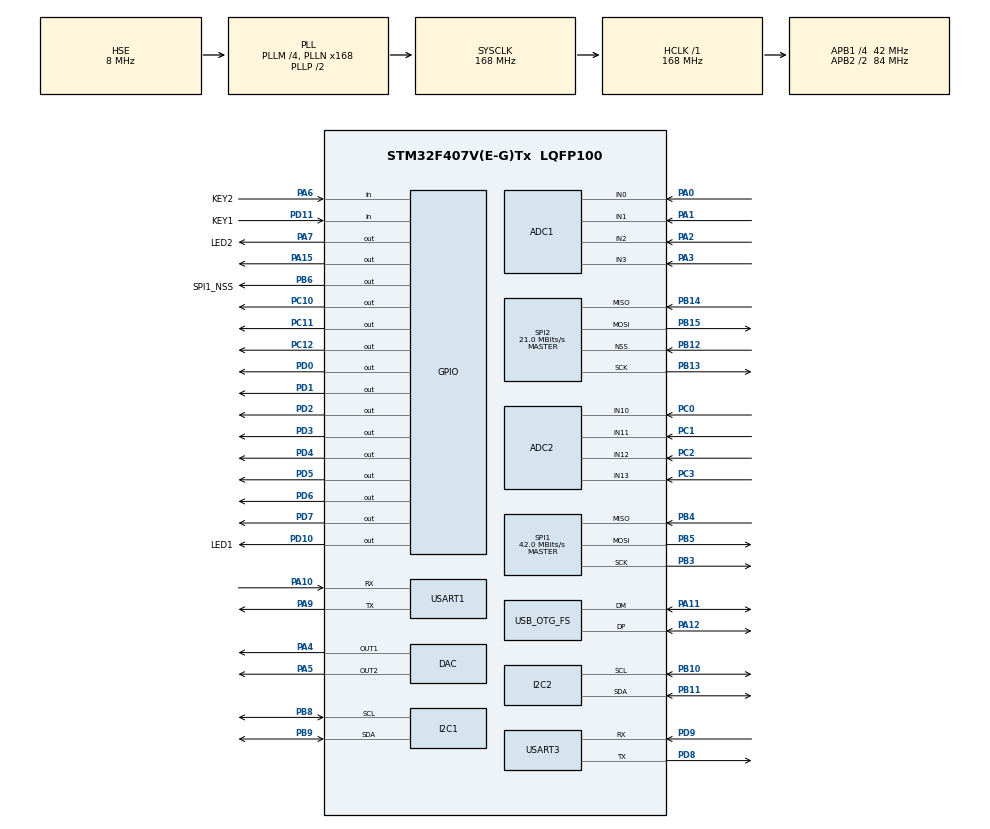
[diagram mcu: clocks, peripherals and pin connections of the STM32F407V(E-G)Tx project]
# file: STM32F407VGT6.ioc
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ADC1.Channel-66\#ChannelRegularConversion=ADC_CHANNEL_0
ADC1.ClockPrescaler=ADC_CLOCK_SYNC_PCLK_DIV4
ADC1.NbrOfConversionFlag=1
ADC1.Rank-66\#ChannelRegularConversion=1
ADC1.SamplingTime-66\#ChannelRegularConversion=ADC_SAMPLETIME_3CYCLES
ADC1.master=1
ADC2.Channel-42\#ChannelRegularConversion=ADC_CHANNEL_10
ADC2.ClockPrescaler=ADC_CLOCK_SYNC_PCLK_DIV4
ADC2.NbrOfConversionFlag=1
ADC2.Rank-42\#ChannelRegularConversion=1
ADC2.SamplingTime-42\#ChannelRegularConversion=ADC_SAMPLETIME_3CYCLES
Mcu.Family=STM32F4
Mcu.Name=STM32F407V(E-G)Tx
Mcu.Package=LQFP100
NVIC.PriorityGroup=NVIC_PRIORITYGROUP_4
PA0-WKUP.Signal=ADCx_IN0
PA1.Signal=ADCx_IN1
PA10.Mode=Asynchronous
PA10.Signal=USART1_RX
PA11.Mode=Device_Only
PA11.Signal=USB_OTG_FS_DM
PA12.Mode=Device_Only
PA12.Signal=USB_OTG_FS_DP
PA13.Mode=Serial_Wire
PA13.Signal=SYS_JTMS-SWDIO
PA14.Mode=Serial_Wire
PA14.Signal=SYS_JTCK-SWCLK
PA15.Signal=GPIO_Output
PA2.Signal=ADCx_IN2
PA3.Signal=ADCx_IN3
PA4.Signal=COMP_DAC1_group
PA5.Signal=COMP_DAC2_group
PA6.GPIO_Label=KEY2
PA6.Signal=GPIO_Input
PA7.GPIO_Label=LED2
PA7.Signal=GPIO_Output
PA9.Mode=Asynchronous
PA9.Signal=USART1_TX
PB10.Mode=I2C
PB10.Signal=I2C2_SCL
PB11.Mode=I2C
PB11.Signal=I2C2_SDA
PB12.Mode=NSS_Signal_Hard_Input
PB12.Signal=SPI2_NSS
PB13.Mode=Full_Duplex_Master
PB13.Signal=SPI2_SCK
PB14.Mode=Full_Duplex_Master
PB14.Signal=SPI2_MISO
PB15.Mode=Full_Duplex_Master
PB15.Signal=SPI2_MOSI
PB3.Mode=Full_Duplex_Master
PB3.Signal=SPI1_SCK
PB4.Mode=Full_Duplex_Master
PB4.Signal=SPI1_MISO
PB5.Mode=Full_Duplex_Master
PB5.Signal=SPI1_MOSI
PB6.GPIO_Label=SPI1_NSS
PB6.Signal=GPIO_Output
PB8.Mode=I2C
PB8.Signal=I2C1_SCL
PB9.Mode=I2C
PB9.Signal=I2C1_SDA
PC0.Signal=ADCx_IN10
PC1.Signal=ADCx_IN11
PC10.Signal=GPIO_Output
PC11.Signal=GPIO_Output
PC12.Signal=GPIO_Output
PC14-OSC32_IN.Mode=LSE-External-Oscillator
PC14-OSC32_IN.Signal=RCC_OSC32_IN
PC15-OSC32_OUT.Mode=LSE-External-Oscillator
PC15-OSC32_OUT.Signal=RCC_OSC32_OUT
PC2.Signal=ADCx_IN12
PC3.Signal=ADCx_IN13
PD0.Signal=GPIO_Output
PD1.Signal=GPIO_Output
PD10.GPIO_Label=LED1
PD10.Signal=GPIO_Output
PD11.GPIO_Label=KEY1
PD11.Signal=GPIO_Input
PD2.Signal=GPIO_Output
PD3.Signal=GPIO_Output
PD4.Signal=GPIO_Output
PD5.Signal=GPIO_Output
PD6.Signal=GPIO_Output
PD7.Signal=GPIO_Output
PD8.Mode=Asynchronous
PD8.Signal=USART3_TX
PD9.Mode=Asynchronous
PD9.Signal=USART3_RX
PH0-OSC_IN.Mode=HSE-External-Oscillator
PH0-OSC_IN.Signal=RCC_OSC_IN
PH1-OSC_OUT.Mode=HSE-External-Oscillator
PH1-OSC_OUT.Signal=RCC_OSC_OUT
ProjectManager.HeapSize=0x200
ProjectManager.StackSize=0x400
ProjectManager.TargetToolchain=MDK-ARM V5
RCC.48MHZClocksFreq_Value=48000000
RCC.AHBFreq_Value=168000000
RCC.APB1CLKDivider=RCC_HCLK_DIV4
RCC.APB1Freq_Value=42000000
RCC.APB1TimFreq_Value=84000000
RCC.APB2CLKDivider=RCC_HCLK_DIV2
RCC.APB2Freq_Value=84000000
RCC.APB2TimFreq_Value=168000000
RCC.CortexFreq_Value=168000000
RCC.HCLKFreq_Value=168000000
RCC.HSE_VALUE=8000000
RCC.HSI_VALUE=16000000
RCC.PLLM=4
RCC.PLLN=168
RCC.PLLQ=7
RCC.SYSCLKFreq_VALUE=168000000
RCC.SYSCLKSource=RCC_SYSCLKSOURCE_PLLCLK
RCC.VCOOutputFreq_Value=336000000
SH.ADCx_IN0.0=ADC1_IN0,IN0
SH.ADCx_IN1.0=ADC1_IN1,IN1
SH.ADCx_IN10.0=ADC2_IN10,IN10
SH.ADCx_IN11.0=ADC2_IN11,IN11
SH.ADCx_IN12.0=ADC2_IN12,IN12
SH.ADCx_IN13.0=ADC2_IN13,IN13
SH.ADCx_IN2.0=ADC1_IN2,IN2
SH.ADCx_IN3.0=ADC1_IN3,IN3
SH.COMP_DAC1_group.0=DAC_OUT1,DAC_OUT1
SH.COMP_DAC2_group.0=DAC_OUT2,DAC_OUT2
SPI1.CalculateBaudRate=42.0 MBits/s
SPI1.Direction=SPI_DIRECTION_2LINES
SPI1.Mode=SPI_MODE_MASTER
SPI1.VirtualType=VM_MASTER
SPI2.CalculateBaudRate=21.0 MBits/s
SPI2.Direction=SPI_DIRECTION_2LINES
SPI2.Mode=SPI_MODE_MASTER
SPI2.VirtualNSS=VM_NSSHARD
SPI2.VirtualType=VM_MASTER
USART1.VirtualMode=VM_ASYNC
USART3.VirtualMode=VM_ASYNC
USB_OTG_FS.VirtualMode=Device_Only
board=custom

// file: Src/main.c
/**
  ******************************************************************************
  * @file           : main.c
  * @brief          : Main program body
  ******************************************************************************
  ** This notice applies to any and all portions of this file
  * that are not between comment pairs USER CODE BEGIN and
  * USER CODE END. Other portions of this file, whether
  * inserted by the user or by software development tools
  * are owned by their respective copyright owners.
  *
  * COPYRIGHT(c) 2019 STMicroelectronics
  *
  * Redistribution and use in source and binary forms, with or without modification,
  * are permitted provided that the following conditions are met:
  *   1. Redistributions of source code must retain the above copyright notice,
  *      this list of conditions and the following disclaimer.
  *   2. Redistributions in binary form must reproduce the above copyright notice,
  *      this list of conditions and the following disclaimer in the documentation
  *      and/or other materials provided with the distribution.
  *   3. Neither the name of STMicroelectronics nor the names of its contributors
  *      may be used to endorse or promote products derived from this software
  *      without specific prior written permission.
  *
  * THIS SOFTWARE IS PROVIDED BY THE COPYRIGHT HOLDERS AND CONTRIBUTORS "AS IS"
  * AND ANY EXPRESS OR IMPLIED WARRANTIES, INCLUDING, BUT NOT LIMITED TO, THE
  * IMPLIED WARRANTIES OF MERCHANTABILITY AND FITNESS FOR A PARTICULAR PURPOSE ARE
  * DISCLAIMED. IN NO EVENT SHALL THE COPYRIGHT HOLDER OR CONTRIBUTORS BE LIABLE
  * FOR ANY DIRECT, INDIRECT, INCIDENTAL, SPECIAL, EXEMPLARY, OR CONSEQUENTIAL
  * DAMAGES (INCLUDING, BUT NOT LIMITED TO, PROCUREMENT OF SUBSTITUTE GOODS OR
  * SERVICES; LOSS OF USE, DATA, OR PROFITS; OR BUSINESS INTERRUPTION) HOWEVER
  * CAUSED AND ON ANY THEORY OF LIABILITY, WHETHER IN CONTRACT, STRICT LIABILITY,
  * OR TORT (INCLUDING NEGLIGENCE OR OTHERWISE) ARISING IN ANY WAY OUT OF THE USE
  * OF THIS SOFTWARE, EVEN IF ADVISED OF THE POSSIBILITY OF SUCH DAMAGE.
  *
  ******************************************************************************
  */
#include "main.h"
#include "stm32f4xx_hal.h"
#include "adc.h"
#include "dac.h"
#include "i2c.h"
#include "spi.h"
#include "usart.h"
#include "usb_otg.h"
#include "gpio.h"

/* USER CODE BEGIN Includes */
#include "stdio.h"
/* USER CODE END Includes */

/* USER CODE BEGIN PV */
/* Private variables ---------------------------------------------------------*/

/* USER CODE END PV */

void SystemClock_Config(void);

/* USER CODE BEGIN PFP */
/* Private function prototypes -----------------------------------------------*/

/* USER CODE END PFP */

int main(void)
{

  /* MCU Configuration----------------------------------------------------------*/

  /* Reset of all peripherals, Initializes the Flash interface and the Systick. */
  HAL_Init();

  /* Configure the system clock */
  SystemClock_Config();

  /* Initialize all configured peripherals */
  MX_GPIO_Init();
  MX_ADC1_Init();
  MX_ADC2_Init();
  MX_DAC_Init();
  MX_I2C1_Init();
  MX_I2C2_Init();
  MX_SPI1_Init();
  MX_SPI2_Init();
  MX_USART1_UART_Init();
  MX_USART3_UART_Init();
  MX_USB_OTG_FS_PCD_Init();
  /* USER CODE BEGIN 2 */
  printf("init ok!\n");

  /* USER CODE END 2 */

  /* Infinite loop */
  /* USER CODE BEGIN WHILE */
  while (1)
  {
	HAL_GPIO_TogglePin(GPIOD, LED1_Pin);
	printf("STM32F407VGT6!\n");
	HAL_Delay(1 * 1000);
  /* USER CODE END WHILE */

  }

}

void SystemClock_Config(void)
{

  RCC_OscInitTypeDef RCC_OscInitStruct;
  RCC_ClkInitTypeDef RCC_ClkInitStruct;

    /**Configure the main internal regulator output voltage
    */
  __HAL_RCC_PWR_CLK_ENABLE();

  __HAL_PWR_VOLTAGESCALING_CONFIG(PWR_REGULATOR_VOLTAGE_SCALE1);

    /**Initializes the CPU, AHB and APB busses clocks
    */
  RCC_OscInitStruct.OscillatorType = RCC_OSCILLATORTYPE_HSE;
  RCC_OscInitStruct.HSEState = RCC_HSE_ON;
  RCC_OscInitStruct.PLL.PLLState = RCC_PLL_ON;
  RCC_OscInitStruct.PLL.PLLSource = RCC_PLLSOURCE_HSE;
  RCC_OscInitStruct.PLL.PLLM = 4;
  RCC_OscInitStruct.PLL.PLLN = 168;
  RCC_OscInitStruct.PLL.PLLP = RCC_PLLP_DIV2;
  RCC_OscInitStruct.PLL.PLLQ = 7;
  if (HAL_RCC_OscConfig(&RCC_OscInitStruct) != HAL_OK)
  {
    _Error_Handler(__FILE__, __LINE__);
  }

    /**Initializes the CPU, AHB and APB busses clocks
    */
  RCC_ClkInitStruct.ClockType = RCC_CLOCKTYPE_HCLK|RCC_CLOCKTYPE_SYSCLK
                              |RCC_CLOCKTYPE_PCLK1|RCC_CLOCKTYPE_PCLK2;
  RCC_ClkInitStruct.SYSCLKSource = RCC_SYSCLKSOURCE_PLLCLK;
  RCC_ClkInitStruct.AHBCLKDivider = RCC_SYSCLK_DIV1;
  RCC_ClkInitStruct.APB1CLKDivider = RCC_HCLK_DIV4;
  RCC_ClkInitStruct.APB2CLKDivider = RCC_HCLK_DIV2;

  if (HAL_RCC_ClockConfig(&RCC_ClkInitStruct, FLASH_LATENCY_5) != HAL_OK)
  {
    _Error_Handler(__FILE__, __LINE__);
  }

    /**Configure the Systick interrupt time
    */
  HAL_SYSTICK_Config(HAL_RCC_GetHCLKFreq()/1000);

    /**Configure the Systick
    */
  HAL_SYSTICK_CLKSourceConfig(SYSTICK_CLKSOURCE_HCLK);

  /* SysTick_IRQn interrupt configuration */
  HAL_NVIC_SetPriority(SysTick_IRQn, 0, 0);
}

void _Error_Handler(char *file, int line)
{
  while(1)
  {
  }
}

/************************ (C) COPYRIGHT STMicroelectronics *****END OF FILE****/
